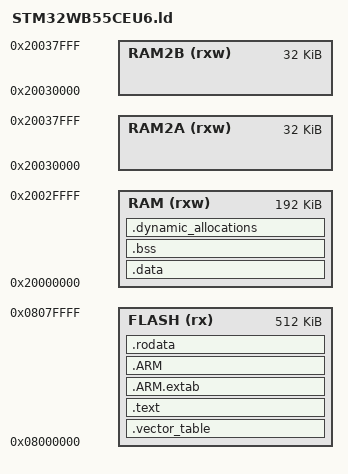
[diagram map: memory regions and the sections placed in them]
/* Label for the program's entry point */
ENTRY(reset_handler)

/* End of RAM/Start of stack */
/* (192KB SRAM in SRAM1) */
_estack = 0x20030000;

/* Set minimum size for stack and dynamic memory. */
/* (The linker will generate an error if there is
 * less than this much RAM leftover.) */
/* (1KB) */
_Min_Leftover_RAM = 0x400;

MEMORY
{
    FLASH ( rx )      : ORIGIN = 0x08000000, LENGTH = 512K
    RAM ( rxw )       : ORIGIN = 0x20000000, LENGTH = 192K
    RAM2A ( rxw )     : ORIGIN = 0x20030000, LENGTH = 32K
    RAM2B ( rxw )     : ORIGIN = 0x20030000, LENGTH = 32K
}

SECTIONS
{
  /* The vector table goes to the start of flash. */
  .vector_table :
  {
    . = ALIGN(4);
    KEEP (*(.vector_table))
    . = ALIGN(4);
  } >FLASH

  /* The 'text' section contains the main program code. */
  .text :
  {
    . = ALIGN(4);
    *(.text)
    *(.text*)
    KEEP (*(.init))
    KEEP (*(.fini))
    KEEP (*(.eh_frame))
    . = ALIGN(4);
  } >FLASH

  /* Sections required by the standard libraries. */
  .ARM.extab :
  {
    *(.ARM.extab* .gnu.linkonce.armextab.*)
  } >FLASH
  .ARM :
  {
    *(.ARM.exidx*)
  } >FLASH

  /* The 'rodata' section contains read-only data,
   * constants, strings, information that won't change. */
  .rodata :
  {
    . = ALIGN(4);
    *(.rodata)
    *(.rodata*)
    . = ALIGN(4);
  } >FLASH

  /* The 'data' section is space set aside in RAM for
   * things like variables, which can change. */
  _sidata = .;
  .data : AT(_sidata)
  {
    . = ALIGN(4);
    /* Mark start/end locations for the 'data' section. */
    _sdata = .;
    *(.data)
    *(.data*)
    _edata = .;
    . = ALIGN(4);
  } >RAM

  /* The 'bss' section is similar to the 'data' section,
   * but its space is initialized to all 0s at the
   * start of the program. */
  .bss :
  {
    . = ALIGN(4);
    /* Also mark the start/end of the BSS section. */
    _sbss = .;
    __bss_start__ = _sbss;
    *(.bss)
    *(.bss*)
    *(COMMON)
    . = ALIGN(4);
    _ebss = .;
    __bss_end__ = _ebss;
  } >RAM
  /* Mark the end of statically-allocated RAM. */
  end = .;
  _end = end;
  __end = end;

  /* Space set aside for the application's heap/stack. */
  .dynamic_allocations :
  {
    . = ALIGN(4);
    _ssystem_ram = .;
    . = . + _Min_Leftover_RAM;
    . = ALIGN(4);
    _esystem_ram = .;
  } >RAM
}
